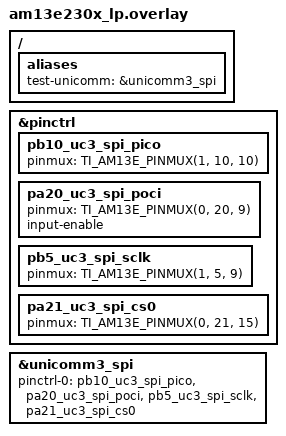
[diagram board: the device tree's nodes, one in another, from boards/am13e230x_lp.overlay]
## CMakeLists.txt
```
# SPDX-License-Identifier: Apache-2.0

cmake_minimum_required(VERSION 3.20.0)
find_package(Zephyr REQUIRED HINTS $ENV{ZEPHYR_BASE})
project(spi_loopback_test)

target_sources(app PRIVATE src/main.c)
```

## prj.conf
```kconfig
CONFIG_GPIO=y

CONFIG_SERIAL=y
CONFIG_CONSOLE=y
CONFIG_UART_CONSOLE=y

CONFIG_COMPILER_SAVE_TEMPS=y

CONFIG_SPI=y
```

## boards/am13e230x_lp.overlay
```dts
/*
 * Copyright (c) 2026 Texas Instruments Incorporated
 *
 * SPDX-License-Identifier: Apache-2.0
 */

/ {
	aliases {
		test-unicomm = &unicomm3_spi;
	};
};

&pinctrl {
	status = "okay";

	pb10_uc3_spi_pico: pb10_uc3_spi_pico {
		pinmux = <TI_AM13E_PINMUX(1, 10, 10)>;
	};

	pa20_uc3_spi_poci: pa20_uc3_spi_poci {
		pinmux = <TI_AM13E_PINMUX(0, 20, 9)>;
		input-enable;
	};

	pb5_uc3_spi_sclk: pb5_uc3_spi_sclk {
		pinmux = <TI_AM13E_PINMUX(1, 5, 9)>;
	};

	pa21_uc3_spi_cs0: pa21_uc3_spi_cs0 {
		pinmux = <TI_AM13E_PINMUX(0, 21, 15)>;
	};
};

&unicomm3_spi {
	status = "okay";

	pinctrl-0 = <&pb10_uc3_spi_pico &pa20_uc3_spi_poci &pb5_uc3_spi_sclk &pa21_uc3_spi_cs0>;
	pinctrl-names = "default";
};
```

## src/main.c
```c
/*
 * Copyright (c) 2026 Texas Instruments Incorporated
 *
 * SPDX-License-Identifier: Apache-2.0
 */

#include <stdio.h>
#include <zephyr/kernel.h>
#include <zephyr/drivers/spi.h>

/* SPI config */
#define SPI_NODE DT_ALIAS(test_unicomm)

static const struct device *spi_dev = DEVICE_DT_GET(SPI_NODE);
static const struct spi_config spi_cfg = {
	.frequency = 1000000,
	.operation = SPI_WORD_SET(8) | SPI_TRANSFER_MSB | SPI_MODE_CPHA,
	.slave = 0,
};

#define ALPHABET_LEN 26

int main(void)
{
	int ret;

	uint8_t tx_buffer[ALPHABET_LEN];
	uint8_t rx_buffer[ALPHABET_LEN];

	printk("Starting SPI Alphabet Transfer Sample\n");

	/* Verify that the SPI device is ready */
	if (!device_is_ready(spi_dev)) {
		printk("SPI device not ready\n");
		return -ENODEV;
	}

	/* Initialize the transmit buffer with the uppercase alphabet */
	for (int i = 0; i < ALPHABET_LEN; i++) {
		tx_buffer[i] = 'A' + i;
	}

    /* Set up the SPI buffer structures */
    const struct spi_buf tx_buf = {
        .buf = tx_buffer,
        .len = sizeof(tx_buffer)
    };
    const struct spi_buf_set tx_bufs = {
        .buffers = &tx_buf,
        .count = 1
    };

    struct spi_buf rx_buf = {
        .buf = rx_buffer,
        .len = sizeof(rx_buffer)
    };
    const struct spi_buf_set rx_bufs = {
        .buffers = &rx_buf,
        .count = 1
    };

    while (1) {
        printk("Transmitting alphabet ('A'-'Z')... ");

        /* Perform synchronous full-duplex SPI transfer */
        ret = spi_transceive(spi_dev, &spi_cfg, &tx_bufs, &rx_bufs);
        if (ret < 0) {
            printk("SPI transceive failed with error: %d", ret);
        } else {
            printk("Transfer complete.\n");
            /* If MISO is tied to MOSI (loopback), rx_buffer will hold the alphabet */
	    printk("Received data: ");
	    for (int j=0; j<ALPHABET_LEN; j++) {
		    printk("%c,", rx_buffer[j]);
		}
	    printk("\n");
        }

        /* Wait 2 seconds before sending again */
        k_msleep(2000);
    }

	return 0;
}
```
